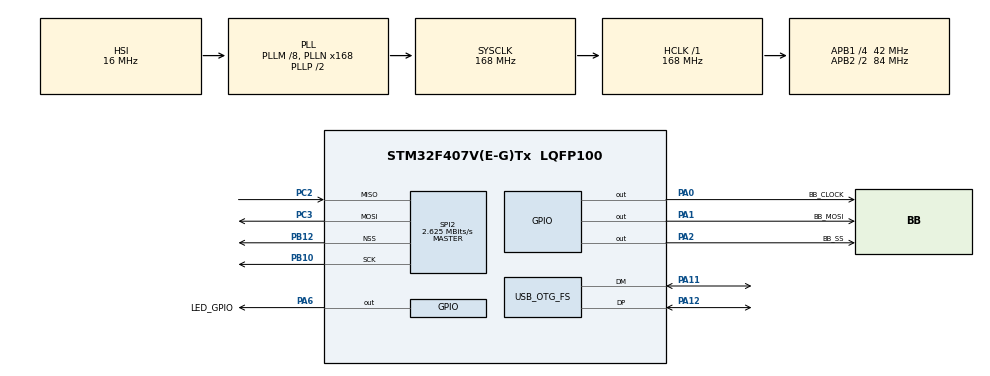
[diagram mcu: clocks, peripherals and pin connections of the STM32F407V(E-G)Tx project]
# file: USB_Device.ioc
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Mcu.Family=STM32F4
Mcu.Name=STM32F407V(E-G)Tx
Mcu.Package=LQFP100
NVIC.OTG_FS_IRQn=true\:0\:0\:false\:false\:true\:false\:true
NVIC.PriorityGroup=NVIC_PRIORITYGROUP_4
NVIC.TIM2_IRQn=true\:0\:0\:false\:false\:true\:true\:true
PA0-WKUP.GPIO_Label=BB_CLOCK
PA0-WKUP.GPIO_Speed=GPIO_SPEED_FREQ_VERY_HIGH
PA0-WKUP.Signal=GPIO_Output
PA1.GPIO_Label=BB_MOSI
PA1.GPIO_Speed=GPIO_SPEED_FREQ_VERY_HIGH
PA1.Signal=GPIO_Output
PA11.Mode=Device_Only
PA11.Signal=USB_OTG_FS_DM
PA12.Mode=Device_Only
PA12.Signal=USB_OTG_FS_DP
PA2.GPIO_Label=BB_SS
PA2.GPIO_Speed=GPIO_SPEED_FREQ_VERY_HIGH
PA2.Signal=GPIO_Output
PA6.GPIO_Label=LED_GPIO
PA6.Signal=GPIO_Output
PB10.Mode=Full_Duplex_Master
PB10.Signal=SPI2_SCK
PB12.Mode=NSS_Signal_Hard_Output
PB12.Signal=SPI2_NSS
PC2.Mode=Full_Duplex_Master
PC2.Signal=SPI2_MISO
PC3.Mode=Full_Duplex_Master
PC3.Signal=SPI2_MOSI
PH0-OSC_IN.Mode=HSE-External-Oscillator
PH0-OSC_IN.Signal=RCC_OSC_IN
PH1-OSC_OUT.Mode=HSE-External-Oscillator
PH1-OSC_OUT.Signal=RCC_OSC_OUT
ProjectManager.HeapSize=0x200
ProjectManager.StackSize=0x400
ProjectManager.TargetToolchain=STM32CubeIDE
RCC.48MHZClocksFreq_Value=48000000
RCC.AHBFreq_Value=168000000
RCC.APB1CLKDivider=RCC_HCLK_DIV4
RCC.APB1Freq_Value=42000000
RCC.APB1TimFreq_Value=84000000
RCC.APB2CLKDivider=RCC_HCLK_DIV2
RCC.APB2Freq_Value=84000000
RCC.APB2TimFreq_Value=168000000
RCC.CortexFreq_Value=168000000
RCC.HCLKFreq_Value=168000000
RCC.HSE_VALUE=16000000
RCC.HSI_VALUE=16000000
RCC.LSE_VALUE=32768
RCC.PLLM=8
RCC.PLLN=168
RCC.PLLQ=7
RCC.PLLSource=RCC_PLLSOURCE_HSI
RCC.PLLSourceVirtualString=RCC_PLLSOURCE_HSI
RCC.SYSCLKFreq_VALUE=168000000
RCC.SYSCLKSource=RCC_SYSCLKSOURCE_PLLCLK
RCC.VCOOutputFreq_Value=336000000
SPI2.BaudRatePrescaler=SPI_BAUDRATEPRESCALER_16
SPI2.CalculateBaudRate=2.625 MBits/s
SPI2.Direction=SPI_DIRECTION_2LINES
SPI2.FirstBit=SPI_FIRSTBIT_MSB
SPI2.Mode=SPI_MODE_MASTER
SPI2.VirtualNSS=VM_NSSHARD
SPI2.VirtualType=VM_MASTER
TIM2.Period=1000
TIM2.Prescaler=16000
USB_DEVICE.CLASS_NAME_FS=CDC
USB_DEVICE.PRODUCT_STRING_CDC_FS=Bilal Virtual ComPort
USB_DEVICE.VirtualMode-CDC_FS=Cdc
USB_DEVICE.VirtualModeFS=Cdc_FS
USB_OTG_FS.VirtualMode=Device_Only
VP_TIM2_VS_ClockSourceINT.Mode=Internal
VP_USB_DEVICE_VS_USB_DEVICE_CDC_FS.Mode=CDC_FS
board=custom

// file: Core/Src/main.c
/* USER CODE BEGIN Header */
/**
  ******************************************************************************
  * @file           : main.c
  * @brief          : Main program body
  ******************************************************************************
  * @attention
  *
  * <h2><center>&copy; Copyright (c) 2021 STMicroelectronics.
  * All rights reserved.</center></h2>
  *
  * This software component is licensed by ST under BSD 3-Clause license,
  * the "License"; You may not use this file except in compliance with the
  * License. You may obtain a copy of the License at:
  *                        opensource.org/licenses/BSD-3-Clause
  *
  ******************************************************************************
  */
/* USER CODE END Header */
#include "main.h"
#include "usb_device.h"

/* USER CODE BEGIN Includes */
#include "Oled.h"
/* USER CODE END Includes */

SPI_HandleTypeDef hspi2;

TIM_HandleTypeDef htim2;

void SystemClock_Config(void);
static void MX_GPIO_Init(void);
static void MX_TIM2_Init(void);
static void MX_SPI2_Init(void);

int main(void)
{

  /* MCU Configuration--------------------------------------------------------*/

  /* Reset of all peripherals, Initializes the Flash interface and the Systick. */
  HAL_Init();

  /* Configure the system clock */
  SystemClock_Config();

  /* Initialize all configured peripherals */
  MX_GPIO_Init();
  MX_TIM2_Init();
  MX_USB_DEVICE_Init();
  MX_SPI2_Init();
  /* USER CODE BEGIN 2 */
  HAL_TIM_Base_Start_IT(&htim2);
  OLED_Init();

  char startingMsg[] = "Waiting...";
  OLED_Display1(startingMsg, sizeof(startingMsg));
  /* USER CODE END 2 */

  /* Infinite loop */
  while (1)
  {

  }
}

void SystemClock_Config(void)
{
  RCC_OscInitTypeDef RCC_OscInitStruct = {0};
  RCC_ClkInitTypeDef RCC_ClkInitStruct = {0};

  /** Configure the main internal regulator output voltage
  */
  __HAL_RCC_PWR_CLK_ENABLE();
  __HAL_PWR_VOLTAGESCALING_CONFIG(PWR_REGULATOR_VOLTAGE_SCALE1);
  /** Initializes the RCC Oscillators according to the specified parameters
  * in the RCC_OscInitTypeDef structure.
  */
  RCC_OscInitStruct.OscillatorType = RCC_OSCILLATORTYPE_HSI;
  RCC_OscInitStruct.HSIState = RCC_HSI_ON;
  RCC_OscInitStruct.HSICalibrationValue = RCC_HSICALIBRATION_DEFAULT;
  RCC_OscInitStruct.PLL.PLLState = RCC_PLL_ON;
  RCC_OscInitStruct.PLL.PLLSource = RCC_PLLSOURCE_HSI;
  RCC_OscInitStruct.PLL.PLLM = 8;
  RCC_OscInitStruct.PLL.PLLN = 168;
  RCC_OscInitStruct.PLL.PLLP = RCC_PLLP_DIV2;
  RCC_OscInitStruct.PLL.PLLQ = 7;
  if (HAL_RCC_OscConfig(&RCC_OscInitStruct) != HAL_OK)
  {
    Error_Handler();
  }
  /** Initializes the CPU, AHB and APB buses clocks
  */
  RCC_ClkInitStruct.ClockType = RCC_CLOCKTYPE_HCLK|RCC_CLOCKTYPE_SYSCLK
                              |RCC_CLOCKTYPE_PCLK1|RCC_CLOCKTYPE_PCLK2;
  RCC_ClkInitStruct.SYSCLKSource = RCC_SYSCLKSOURCE_PLLCLK;
  RCC_ClkInitStruct.AHBCLKDivider = RCC_SYSCLK_DIV1;
  RCC_ClkInitStruct.APB1CLKDivider = RCC_HCLK_DIV4;
  RCC_ClkInitStruct.APB2CLKDivider = RCC_HCLK_DIV2;

  if (HAL_RCC_ClockConfig(&RCC_ClkInitStruct, FLASH_LATENCY_5) != HAL_OK)
  {
    Error_Handler();
  }
}

static void MX_SPI2_Init(void)
{

  /* SPI2 parameter configuration*/
  hspi2.Instance = SPI2;
  hspi2.Init.Mode = SPI_MODE_MASTER;
  hspi2.Init.Direction = SPI_DIRECTION_2LINES;
  hspi2.Init.DataSize = SPI_DATASIZE_8BIT;
  hspi2.Init.CLKPolarity = SPI_POLARITY_LOW;
  hspi2.Init.CLKPhase = SPI_PHASE_1EDGE;
  hspi2.Init.NSS = SPI_NSS_HARD_OUTPUT;
  hspi2.Init.BaudRatePrescaler = SPI_BAUDRATEPRESCALER_16;
  hspi2.Init.FirstBit = SPI_FIRSTBIT_MSB;
  hspi2.Init.TIMode = SPI_TIMODE_DISABLE;
  hspi2.Init.CRCCalculation = SPI_CRCCALCULATION_DISABLE;
  hspi2.Init.CRCPolynomial = 10;
  if (HAL_SPI_Init(&hspi2) != HAL_OK)
  {
    Error_Handler();
  }

}

static void MX_TIM2_Init(void)
{

  TIM_ClockConfigTypeDef sClockSourceConfig = {0};
  TIM_MasterConfigTypeDef sMasterConfig = {0};

  htim2.Instance = TIM2;
  htim2.Init.Prescaler = 16000;
  htim2.Init.CounterMode = TIM_COUNTERMODE_UP;
  htim2.Init.Period = 1000;
  htim2.Init.ClockDivision = TIM_CLOCKDIVISION_DIV1;
  htim2.Init.AutoReloadPreload = TIM_AUTORELOAD_PRELOAD_DISABLE;
  if (HAL_TIM_Base_Init(&htim2) != HAL_OK)
  {
    Error_Handler();
  }
  sClockSourceConfig.ClockSource = TIM_CLOCKSOURCE_INTERNAL;
  if (HAL_TIM_ConfigClockSource(&htim2, &sClockSourceConfig) != HAL_OK)
  {
    Error_Handler();
  }
  sMasterConfig.MasterOutputTrigger = TIM_TRGO_RESET;
  sMasterConfig.MasterSlaveMode = TIM_MASTERSLAVEMODE_DISABLE;
  if (HAL_TIMEx_MasterConfigSynchronization(&htim2, &sMasterConfig) != HAL_OK)
  {
    Error_Handler();
  }

}

static void MX_GPIO_Init(void)
{
  GPIO_InitTypeDef GPIO_InitStruct = {0};

  /* GPIO Ports Clock Enable */
  __HAL_RCC_GPIOH_CLK_ENABLE();
  __HAL_RCC_GPIOC_CLK_ENABLE();
  __HAL_RCC_GPIOA_CLK_ENABLE();
  __HAL_RCC_GPIOB_CLK_ENABLE();

  /*Configure GPIO pin Output Level */
  HAL_GPIO_WritePin(GPIOA, BB_CLOCK_Pin|BB_MOSI_Pin|BB_SS_Pin|LED_GPIO_Pin, GPIO_PIN_RESET);

  /*Configure GPIO pins : BB_CLOCK_Pin BB_MOSI_Pin BB_SS_Pin */
  GPIO_InitStruct.Pin = BB_CLOCK_Pin|BB_MOSI_Pin|BB_SS_Pin;
  GPIO_InitStruct.Mode = GPIO_MODE_OUTPUT_PP;
  GPIO_InitStruct.Pull = GPIO_NOPULL;
  GPIO_InitStruct.Speed = GPIO_SPEED_FREQ_VERY_HIGH;
  HAL_GPIO_Init(GPIOA, &GPIO_InitStruct);

  /*Configure GPIO pin : LED_GPIO_Pin */
  GPIO_InitStruct.Pin = LED_GPIO_Pin;
  GPIO_InitStruct.Mode = GPIO_MODE_OUTPUT_PP;
  GPIO_InitStruct.Pull = GPIO_NOPULL;
  GPIO_InitStruct.Speed = GPIO_SPEED_FREQ_LOW;
  HAL_GPIO_Init(LED_GPIO_GPIO_Port, &GPIO_InitStruct);

}

/* USER CODE BEGIN 4 */
void HAL_TIM_PeriodElapsedCallback(TIM_HandleTypeDef *htim)
{
  // Check which version of the timer triggered this callback and toggle LED
  if (htim == &htim2)
  {
	  OLED_DisplayLastMessage();
	  HAL_GPIO_TogglePin(LED_GPIO_GPIO_Port, LED_GPIO_Pin);
  }
}
/* USER CODE END 4 */

void Error_Handler(void)
{
  __disable_irq();
  while (1)
  {
  }
}

/************************ (C) COPYRIGHT STMicroelectronics *****END OF FILE****/
